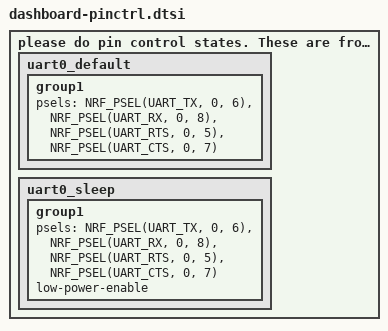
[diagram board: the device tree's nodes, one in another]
/*
 * Copyright (c) HyTech Racing
 * SPDX-License-Identifier: Apache-2.0
 */

#TODO: please do pin control states. These are from base and we likely want something else

&pinctrl {
	uart0_default: uart0_default {
		group1 {
			psels = <NRF_PSEL(UART_TX, 0, 6)>,
				<NRF_PSEL(UART_RX, 0, 8)>,
				<NRF_PSEL(UART_RTS, 0, 5)>,
				<NRF_PSEL(UART_CTS, 0, 7)>;
		};
	};

	uart0_sleep: uart0_sleep {
		group1 {
			psels = <NRF_PSEL(UART_TX, 0, 6)>,
				<NRF_PSEL(UART_RX, 0, 8)>,
				<NRF_PSEL(UART_RTS, 0, 5)>,
				<NRF_PSEL(UART_CTS, 0, 7)>;
			low-power-enable;
		};
	};

};
